# BL602 register map
Vendor: Bouffalo Lab; File version: 1.0
BL602 Wi-Fi + BLE combo chipset
Registers are 8-bit, read-write, reset 0x0 unless marked. A register's access mark holds for its fields unless they carry their own. Offsets are from the block's base; lines under a group give offsets from that group; [hi:lo] are bit positions; {n}, {i} and the like mark numbered series; 'fields as' and 'values as' point back to an identical list; <NAME> marks a mode.

## Memory map
0x02000000 CLIC — RISC-V Core-Local Interrupt Controller
0x40000000 GLB — GLB (todo)
0x40001000 RF — RF (todo)
0x40002000 GPIP — GPIP (todo)
0x40003000 SEC_DBG — SEC_DBG (todo)
0x40004000 SEC_ENG — SEC_ENG (todo)
0x40005000 TZC_SEC — TZC_SEC (todo)
0x40006000 TZC_NSEC — TZC_NSEC (todo)
0x40007000 EF_DATA — EF_DATA (todo)
0x40007000 EF_CTRL — EF_CTRL (todo)
0x40008000 CCI — CCI (todo)
0x40009000 L1C — L1C (todo)
0x4000A000 UART0 — UART0 (todo)
0x4000A100 UART1 — Universal Asynchronous Receiver-Transmitter 1
0x4000A200 SPI — SPI (todo)
0x4000A300 I2C — I2C (todo)
0x4000A400 PWM — PWM (todo)
0x4000A500 TIMER — TIMER (todo)
0x4000A600 IR — IR (todo)
0x4000B000 SF_CTRL — SF_CTRL (todo)
0x4000B700 SF_CTRL_BUF — SF_CTRL_BUF (todo)
0x4000C000 DMA — DMA (todo)
0x4000D000 SDU — SDU (todo)
0x4000E000 PDS — PDS (todo)
0x4000F000 HBN — HBN (todo)
0x4000F000 AON — AON (todo)
0x40010000 HBN_RAM — HBN_RAM (todo)

## UART0 — UART0 (todo)
Base 0x4000A000
Same registers: UART1 0x4000A100

## CLIC — RISC-V Core-Local Interrupt Controller
Base 0x02000000
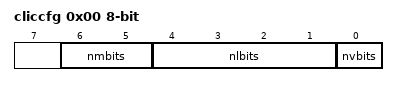
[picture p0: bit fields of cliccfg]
0x00 cliccfg — CLIC Configuration
  [6:5] nmbits — specifies how many bits of actual registers are implemented in clicintattr[i].mode to represent an input i's privilege mode.
  [4:1] nlbits — indicates how many upper bits in clicintctl[i] are assigned to encode the interrupt level. Valid values are 0—​8.
  [0] nvbits — specifies whether the selective interrupt hardware vectoring feature is implemented or not.
0x04 clicinfo 64-bit (reset mask 0xFFFFFFFF) — CLIC Information

## Notices in the file
Copyright (c) 2020 Sipeed Co.,Ltd.
bl602-pac is licensed under Mulan PSL v2.
You can use this software according to the terms and conditions of the Mulan PSL v2.
You may obtain a copy of Mulan PSL v2 at:
http://license.coscl.org.cn/MulanPSL2
THIS SOFTWARE IS PROVIDED ON AN "AS IS" BASIS, WITHOUT WARRANTIES OF ANY KIND,
EITHER EXPRESS OR IMPLIED, INCLUDING BUT NOT LIMITED TO NON-INFRINGEMENT,
MERCHANTABILITY OR FIT FOR A PARTICULAR PURPOSE.
